VERSION "ZephyrECU CI fixtures"
NS_ :

BS_:
BU_: ECU Tester

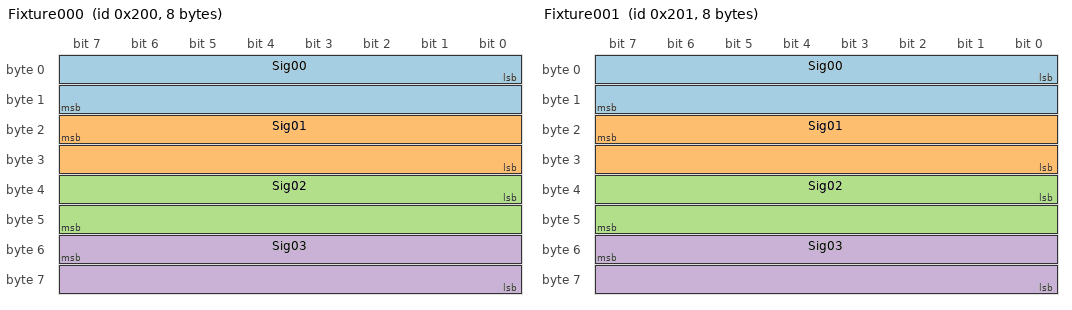
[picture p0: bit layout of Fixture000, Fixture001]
BO_ 512 Fixture000: 8 ECU
 SG_ Sig00 : 0|16@1+ (1,0) [0|65535] "" Tester
 SG_ Sig01 : 23|16@0- (1,0) [-32768|32767] "" Tester
 SG_ Sig02 : 32|16@1+ (1,0) [0|65535] "" Tester
 SG_ Sig03 : 55|16@0- (1,0) [-32768|32767] "" Tester

BO_ 513 Fixture001: 8 Tester
 SG_ Sig00 : 0|16@1+ (1,0) [0|65535] "" ECU
 SG_ Sig01 : 23|16@0- (1,0) [-32768|32767] "" ECU
 SG_ Sig02 : 32|16@1+ (1,0) [0|65535] "" ECU
 SG_ Sig03 : 55|16@0- (1,0) [-32768|32767] "" ECU

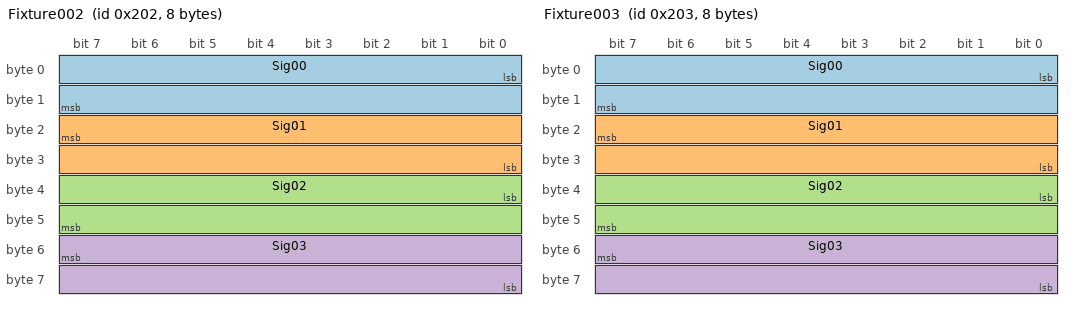
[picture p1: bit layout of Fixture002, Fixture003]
BO_ 514 Fixture002: 8 ECU
 SG_ Sig00 : 0|16@1+ (1,0) [0|65535] "" Tester
 SG_ Sig01 : 23|16@0- (1,0) [-32768|32767] "" Tester
 SG_ Sig02 : 32|16@1+ (1,0) [0|65535] "" Tester
 SG_ Sig03 : 55|16@0- (1,0) [-32768|32767] "" Tester

BO_ 515 Fixture003: 8 Tester
 SG_ Sig00 : 0|16@1+ (1,0) [0|65535] "" ECU
 SG_ Sig01 : 23|16@0- (1,0) [-32768|32767] "" ECU
 SG_ Sig02 : 32|16@1+ (1,0) [0|65535] "" ECU
 SG_ Sig03 : 55|16@0- (1,0) [-32768|32767] "" ECU

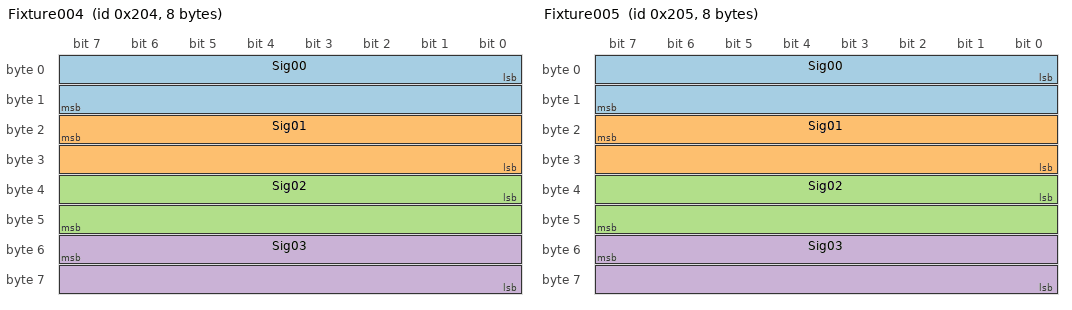
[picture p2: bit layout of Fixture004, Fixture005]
BO_ 516 Fixture004: 8 ECU
 SG_ Sig00 : 0|16@1+ (1,0) [0|65535] "" Tester
 SG_ Sig01 : 23|16@0- (1,0) [-32768|32767] "" Tester
 SG_ Sig02 : 32|16@1+ (1,0) [0|65535] "" Tester
 SG_ Sig03 : 55|16@0- (1,0) [-32768|32767] "" Tester

BO_ 517 Fixture005: 8 Tester
 SG_ Sig00 : 0|16@1+ (1,0) [0|65535] "" ECU
 SG_ Sig01 : 23|16@0- (1,0) [-32768|32767] "" ECU
 SG_ Sig02 : 32|16@1+ (1,0) [0|65535] "" ECU
 SG_ Sig03 : 55|16@0- (1,0) [-32768|32767] "" ECU

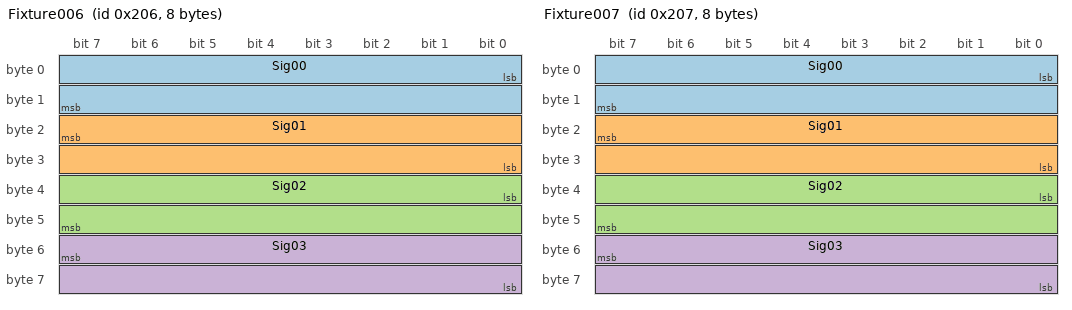
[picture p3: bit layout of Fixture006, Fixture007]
BO_ 518 Fixture006: 8 ECU
 SG_ Sig00 : 0|16@1+ (1,0) [0|65535] "" Tester
 SG_ Sig01 : 23|16@0- (1,0) [-32768|32767] "" Tester
 SG_ Sig02 : 32|16@1+ (1,0) [0|65535] "" Tester
 SG_ Sig03 : 55|16@0- (1,0) [-32768|32767] "" Tester

BO_ 519 Fixture007: 8 Tester
 SG_ Sig00 : 0|16@1+ (1,0) [0|65535] "" ECU
 SG_ Sig01 : 23|16@0- (1,0) [-32768|32767] "" ECU
 SG_ Sig02 : 32|16@1+ (1,0) [0|65535] "" ECU
 SG_ Sig03 : 55|16@0- (1,0) [-32768|32767] "" ECU

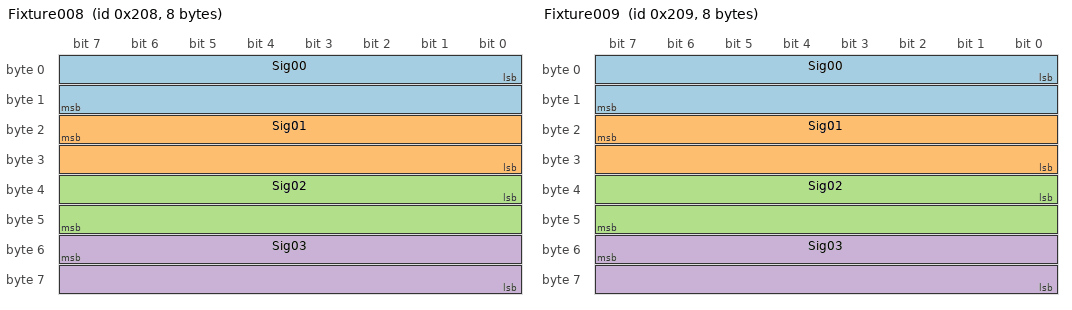
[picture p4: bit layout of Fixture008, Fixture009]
BO_ 520 Fixture008: 8 ECU
 SG_ Sig00 : 0|16@1+ (1,0) [0|65535] "" Tester
 SG_ Sig01 : 23|16@0- (1,0) [-32768|32767] "" Tester
 SG_ Sig02 : 32|16@1+ (1,0) [0|65535] "" Tester
 SG_ Sig03 : 55|16@0- (1,0) [-32768|32767] "" Tester

BO_ 521 Fixture009: 8 Tester
 SG_ Sig00 : 0|16@1+ (1,0) [0|65535] "" ECU
 SG_ Sig01 : 23|16@0- (1,0) [-32768|32767] "" ECU
 SG_ Sig02 : 32|16@1+ (1,0) [0|65535] "" ECU
 SG_ Sig03 : 55|16@0- (1,0) [-32768|32767] "" ECU

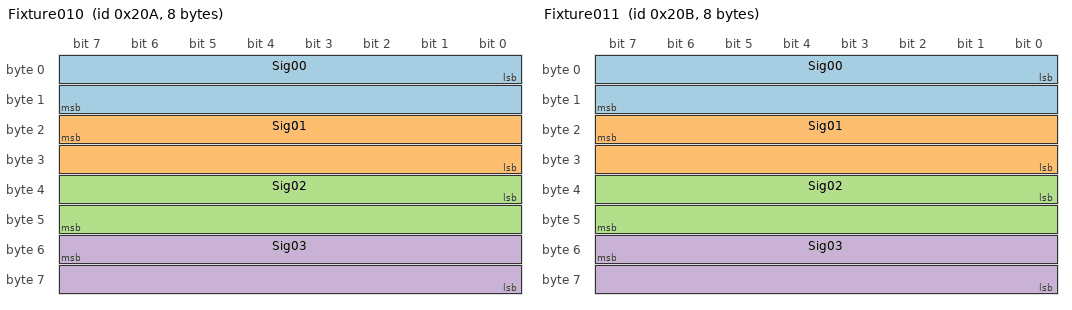
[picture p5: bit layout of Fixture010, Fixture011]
BO_ 522 Fixture010: 8 ECU
 SG_ Sig00 : 0|16@1+ (1,0) [0|65535] "" Tester
 SG_ Sig01 : 23|16@0- (1,0) [-32768|32767] "" Tester
 SG_ Sig02 : 32|16@1+ (1,0) [0|65535] "" Tester
 SG_ Sig03 : 55|16@0- (1,0) [-32768|32767] "" Tester

BO_ 523 Fixture011: 8 Tester
 SG_ Sig00 : 0|16@1+ (1,0) [0|65535] "" ECU
 SG_ Sig01 : 23|16@0- (1,0) [-32768|32767] "" ECU
 SG_ Sig02 : 32|16@1+ (1,0) [0|65535] "" ECU
 SG_ Sig03 : 55|16@0- (1,0) [-32768|32767] "" ECU

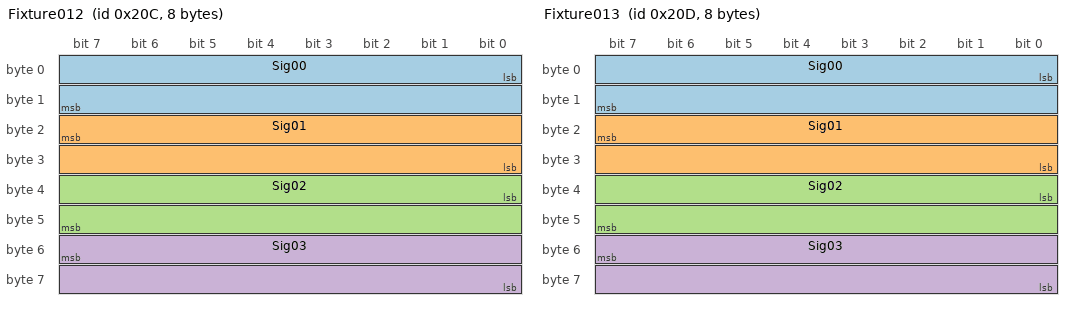
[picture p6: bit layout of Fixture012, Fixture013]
BO_ 524 Fixture012: 8 ECU
 SG_ Sig00 : 0|16@1+ (1,0) [0|65535] "" Tester
 SG_ Sig01 : 23|16@0- (1,0) [-32768|32767] "" Tester
 SG_ Sig02 : 32|16@1+ (1,0) [0|65535] "" Tester
 SG_ Sig03 : 55|16@0- (1,0) [-32768|32767] "" Tester

BO_ 525 Fixture013: 8 Tester
 SG_ Sig00 : 0|16@1+ (1,0) [0|65535] "" ECU
 SG_ Sig01 : 23|16@0- (1,0) [-32768|32767] "" ECU
 SG_ Sig02 : 32|16@1+ (1,0) [0|65535] "" ECU
 SG_ Sig03 : 55|16@0- (1,0) [-32768|32767] "" ECU

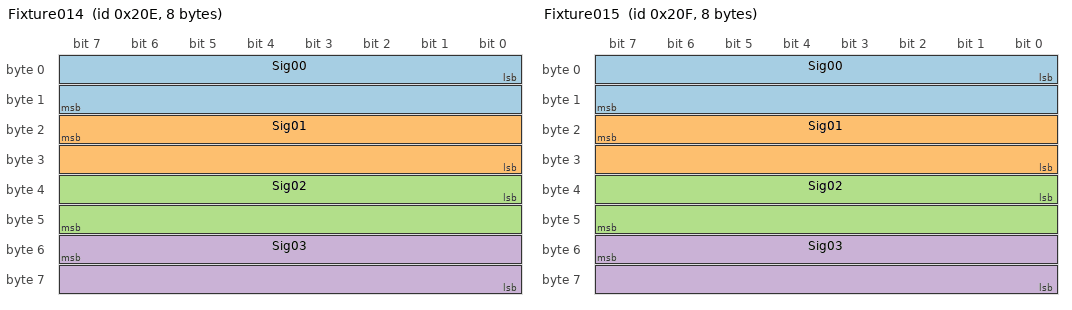
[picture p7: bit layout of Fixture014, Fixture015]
BO_ 526 Fixture014: 8 ECU
 SG_ Sig00 : 0|16@1+ (1,0) [0|65535] "" Tester
 SG_ Sig01 : 23|16@0- (1,0) [-32768|32767] "" Tester
 SG_ Sig02 : 32|16@1+ (1,0) [0|65535] "" Tester
 SG_ Sig03 : 55|16@0- (1,0) [-32768|32767] "" Tester

BO_ 527 Fixture015: 8 Tester
 SG_ Sig00 : 0|16@1+ (1,0) [0|65535] "" ECU
 SG_ Sig01 : 23|16@0- (1,0) [-32768|32767] "" ECU
 SG_ Sig02 : 32|16@1+ (1,0) [0|65535] "" ECU
 SG_ Sig03 : 55|16@0- (1,0) [-32768|32767] "" ECU

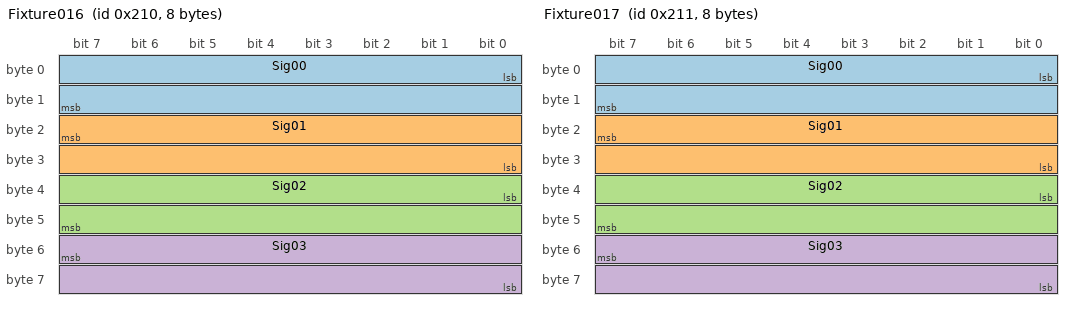
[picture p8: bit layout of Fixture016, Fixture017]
BO_ 528 Fixture016: 8 ECU
 SG_ Sig00 : 0|16@1+ (1,0) [0|65535] "" Tester
 SG_ Sig01 : 23|16@0- (1,0) [-32768|32767] "" Tester
 SG_ Sig02 : 32|16@1+ (1,0) [0|65535] "" Tester
 SG_ Sig03 : 55|16@0- (1,0) [-32768|32767] "" Tester

BO_ 529 Fixture017: 8 Tester
 SG_ Sig00 : 0|16@1+ (1,0) [0|65535] "" ECU
 SG_ Sig01 : 23|16@0- (1,0) [-32768|32767] "" ECU
 SG_ Sig02 : 32|16@1+ (1,0) [0|65535] "" ECU
 SG_ Sig03 : 55|16@0- (1,0) [-32768|32767] "" ECU

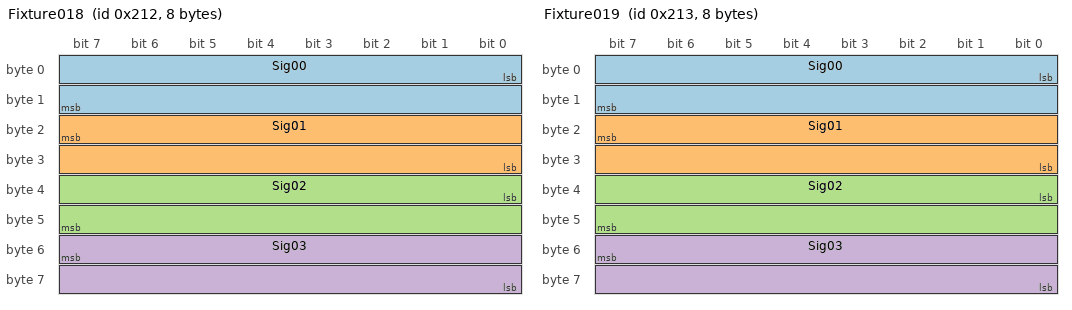
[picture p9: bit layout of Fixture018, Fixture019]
BO_ 530 Fixture018: 8 ECU
 SG_ Sig00 : 0|16@1+ (1,0) [0|65535] "" Tester
 SG_ Sig01 : 23|16@0- (1,0) [-32768|32767] "" Tester
 SG_ Sig02 : 32|16@1+ (1,0) [0|65535] "" Tester
 SG_ Sig03 : 55|16@0- (1,0) [-32768|32767] "" Tester

BO_ 531 Fixture019: 8 Tester
 SG_ Sig00 : 0|16@1+ (1,0) [0|65535] "" ECU
 SG_ Sig01 : 23|16@0- (1,0) [-32768|32767] "" ECU
 SG_ Sig02 : 32|16@1+ (1,0) [0|65535] "" ECU
 SG_ Sig03 : 55|16@0- (1,0) [-32768|32767] "" ECU

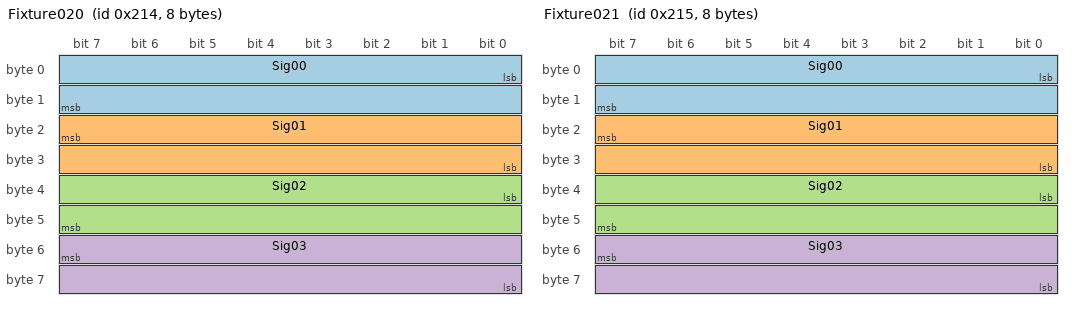
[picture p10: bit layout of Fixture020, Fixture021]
BO_ 532 Fixture020: 8 ECU
 SG_ Sig00 : 0|16@1+ (1,0) [0|65535] "" Tester
 SG_ Sig01 : 23|16@0- (1,0) [-32768|32767] "" Tester
 SG_ Sig02 : 32|16@1+ (1,0) [0|65535] "" Tester
 SG_ Sig03 : 55|16@0- (1,0) [-32768|32767] "" Tester

BO_ 533 Fixture021: 8 Tester
 SG_ Sig00 : 0|16@1+ (1,0) [0|65535] "" ECU
 SG_ Sig01 : 23|16@0- (1,0) [-32768|32767] "" ECU
 SG_ Sig02 : 32|16@1+ (1,0) [0|65535] "" ECU
 SG_ Sig03 : 55|16@0- (1,0) [-32768|32767] "" ECU

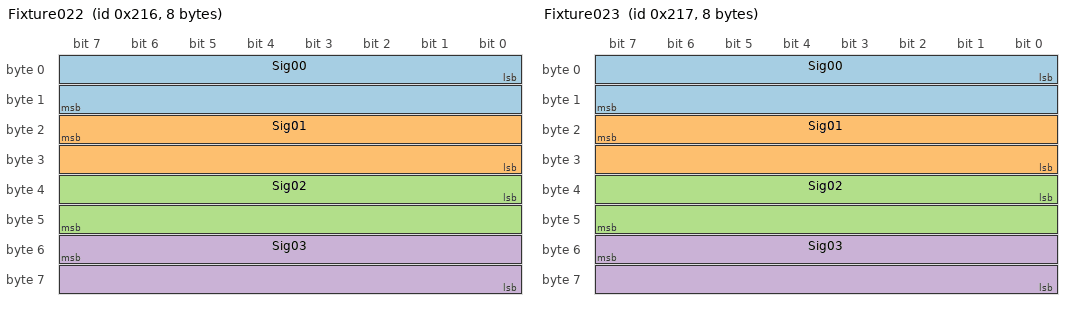
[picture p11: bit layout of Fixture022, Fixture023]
BO_ 534 Fixture022: 8 ECU
 SG_ Sig00 : 0|16@1+ (1,0) [0|65535] "" Tester
 SG_ Sig01 : 23|16@0- (1,0) [-32768|32767] "" Tester
 SG_ Sig02 : 32|16@1+ (1,0) [0|65535] "" Tester
 SG_ Sig03 : 55|16@0- (1,0) [-32768|32767] "" Tester

BO_ 535 Fixture023: 8 Tester
 SG_ Sig00 : 0|16@1+ (1,0) [0|65535] "" ECU
 SG_ Sig01 : 23|16@0- (1,0) [-32768|32767] "" ECU
 SG_ Sig02 : 32|16@1+ (1,0) [0|65535] "" ECU
 SG_ Sig03 : 55|16@0- (1,0) [-32768|32767] "" ECU

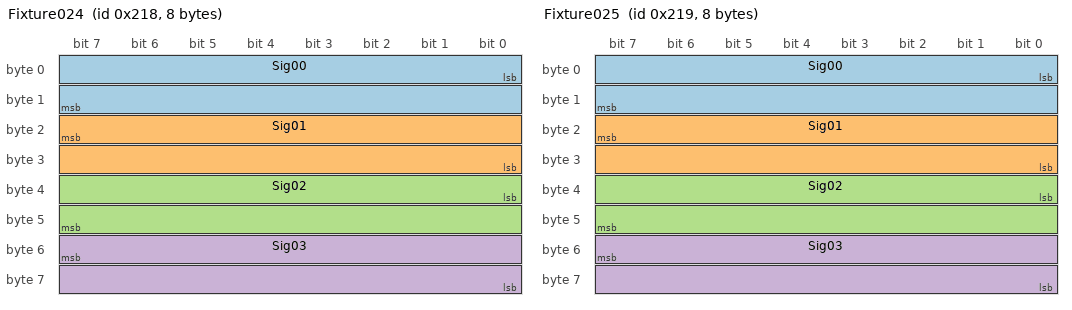
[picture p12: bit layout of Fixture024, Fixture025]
BO_ 536 Fixture024: 8 ECU
 SG_ Sig00 : 0|16@1+ (1,0) [0|65535] "" Tester
 SG_ Sig01 : 23|16@0- (1,0) [-32768|32767] "" Tester
 SG_ Sig02 : 32|16@1+ (1,0) [0|65535] "" Tester
 SG_ Sig03 : 55|16@0- (1,0) [-32768|32767] "" Tester

BO_ 537 Fixture025: 8 Tester
 SG_ Sig00 : 0|16@1+ (1,0) [0|65535] "" ECU
 SG_ Sig01 : 23|16@0- (1,0) [-32768|32767] "" ECU
 SG_ Sig02 : 32|16@1+ (1,0) [0|65535] "" ECU
 SG_ Sig03 : 55|16@0- (1,0) [-32768|32767] "" ECU

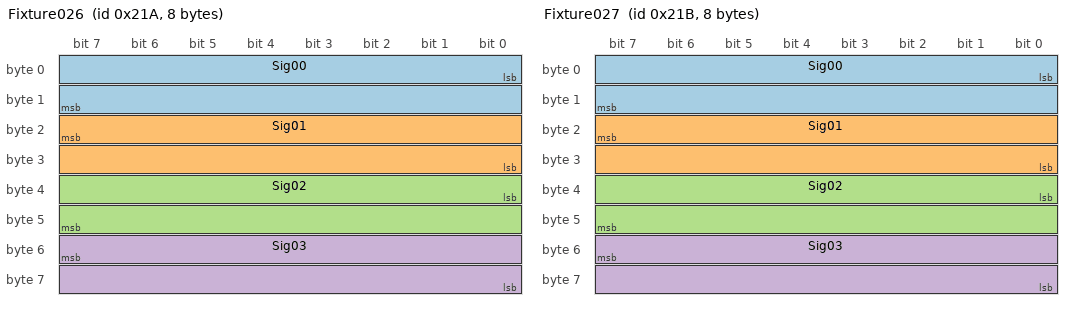
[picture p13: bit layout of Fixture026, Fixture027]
BO_ 538 Fixture026: 8 ECU
 SG_ Sig00 : 0|16@1+ (1,0) [0|65535] "" Tester
 SG_ Sig01 : 23|16@0- (1,0) [-32768|32767] "" Tester
 SG_ Sig02 : 32|16@1+ (1,0) [0|65535] "" Tester
 SG_ Sig03 : 55|16@0- (1,0) [-32768|32767] "" Tester

BO_ 539 Fixture027: 8 Tester
 SG_ Sig00 : 0|16@1+ (1,0) [0|65535] "" ECU
 SG_ Sig01 : 23|16@0- (1,0) [-32768|32767] "" ECU
 SG_ Sig02 : 32|16@1+ (1,0) [0|65535] "" ECU
 SG_ Sig03 : 55|16@0- (1,0) [-32768|32767] "" ECU

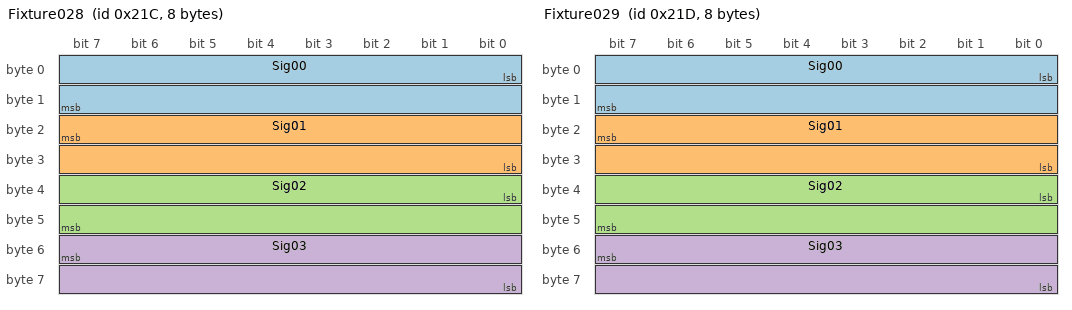
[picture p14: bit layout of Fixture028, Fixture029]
BO_ 540 Fixture028: 8 ECU
 SG_ Sig00 : 0|16@1+ (1,0) [0|65535] "" Tester
 SG_ Sig01 : 23|16@0- (1,0) [-32768|32767] "" Tester
 SG_ Sig02 : 32|16@1+ (1,0) [0|65535] "" Tester
 SG_ Sig03 : 55|16@0- (1,0) [-32768|32767] "" Tester

BO_ 541 Fixture029: 8 Tester
 SG_ Sig00 : 0|16@1+ (1,0) [0|65535] "" ECU
 SG_ Sig01 : 23|16@0- (1,0) [-32768|32767] "" ECU
 SG_ Sig02 : 32|16@1+ (1,0) [0|65535] "" ECU
 SG_ Sig03 : 55|16@0- (1,0) [-32768|32767] "" ECU

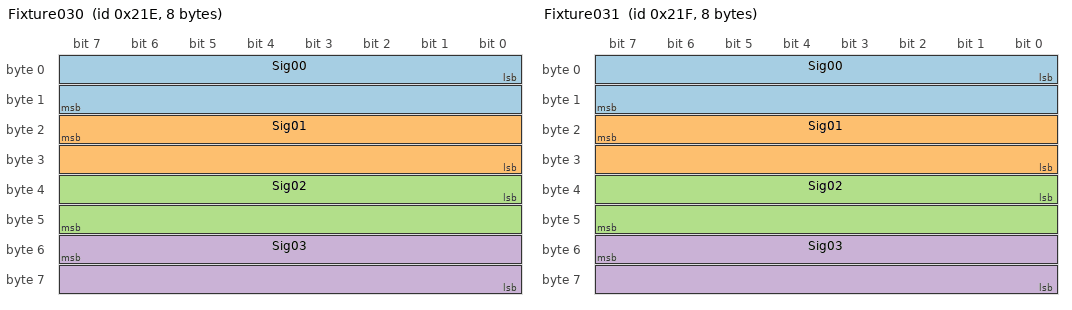
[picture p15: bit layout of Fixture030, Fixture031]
BO_ 542 Fixture030: 8 ECU
 SG_ Sig00 : 0|16@1+ (1,0) [0|65535] "" Tester
 SG_ Sig01 : 23|16@0- (1,0) [-32768|32767] "" Tester
 SG_ Sig02 : 32|16@1+ (1,0) [0|65535] "" Tester
 SG_ Sig03 : 55|16@0- (1,0) [-32768|32767] "" Tester

BO_ 543 Fixture031: 8 Tester
 SG_ Sig00 : 0|16@1+ (1,0) [0|65535] "" ECU
 SG_ Sig01 : 23|16@0- (1,0) [-32768|32767] "" ECU
 SG_ Sig02 : 32|16@1+ (1,0) [0|65535] "" ECU
 SG_ Sig03 : 55|16@0- (1,0) [-32768|32767] "" ECU

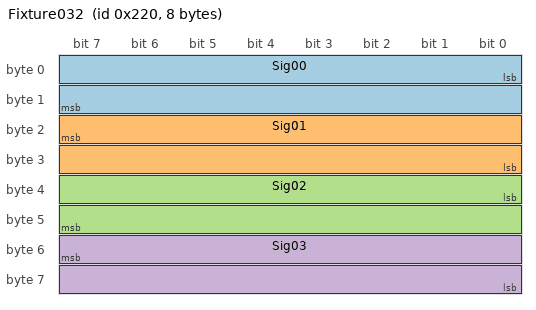
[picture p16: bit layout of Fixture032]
BO_ 544 Fixture032: 8 ECU
 SG_ Sig00 : 0|16@1+ (1,0) [0|65535] "" Tester
 SG_ Sig01 : 23|16@0- (1,0) [-32768|32767] "" Tester
 SG_ Sig02 : 32|16@1+ (1,0) [0|65535] "" Tester
 SG_ Sig03 : 55|16@0- (1,0) [-32768|32767] "" Tester
